# F28x7x_emif_regs register map
Vendor: Texas Instruments
Peripheral module from a debugger description file (folder C2000).
Address unit: 16 bits
Registers are 32-bit, read-write, no defined reset value unless marked. A register's access mark holds for its fields unless they carry their own. Offsets are as the file gives them; lines under a group give offsets from that group; [hi:lo] are bit positions; {n}, {i} and the like mark numbered series; 'fields as' and 'values as' point back to an identical list; <NAME> marks a mode.

## EMIF_REGS
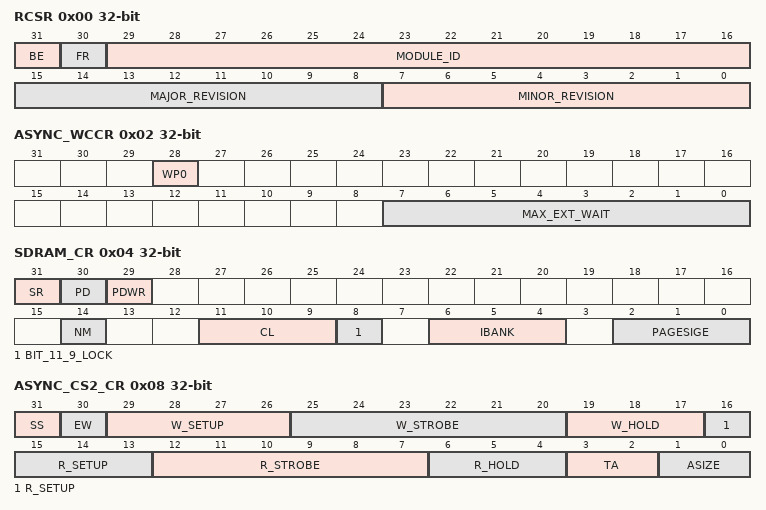
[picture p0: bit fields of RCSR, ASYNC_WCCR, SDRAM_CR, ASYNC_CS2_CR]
0x00 RCSR — Revision Code and Status Register
  [31] BE — EMIF endian mode.
  [30] FR — EMIF is running in full rate or half rate.
  [29:16] MODULE_ID — EMIF module ID.
  [15:8] MAJOR_REVISION
  [7:0] MINOR_REVISION
0x02 ASYNC_WCCR — Async Wait Cycle Config Register
  [28] WP0 — Wait Polarity for EMxWAIT port.
  [7:0] MAX_EXT_WAIT — Maximum Extended Wait cycles.
0x04 SDRAM_CR — SDRAM (EMxCS0n) Config Register
  [31] SR — Self Refresh.
  [30] PD — Power Down.
  [29] PDWR — Perform refreshes during Power Down.
  [14] NM — Narrow Mode.
  [11:9] CL — CAS Latency.
  [8] BIT_11_9_LOCK — Bits 11 to 9 are writable only if this bit is set.
  [6:4] IBANK — Internal Bank setup of SDRAM devices.
  [2:0] PAGESIGE — Page Size.
0x06 SDRAM_RCR — SDRAM Refresh Control Register
  [12:0] REFRESH_RATE
0x08 ASYNC_CS2_CR — Async 1 (EMxCS2n) Config Register
  [31] SS — Select Strobe mode.
  [30] EW — Extend Wait mode.
  [29:26] W_SETUP — Write Strobe Setup cycles.
  [25:20] W_STROBE — Write Strobe Duration cycles.
  [19:17] W_HOLD — Write Strobe Hold cycles.
  [16:13] R_SETUP — Read Strobe Setup cycles.
  [12:7] R_STROBE — Read Strobe Duration cycles.
  [6:4] R_HOLD — Read Strobe Hold cycles.
  [3:2] TA — Turn Around cycles.
  [1:0] ASIZE — Asynchronous Memory Size.
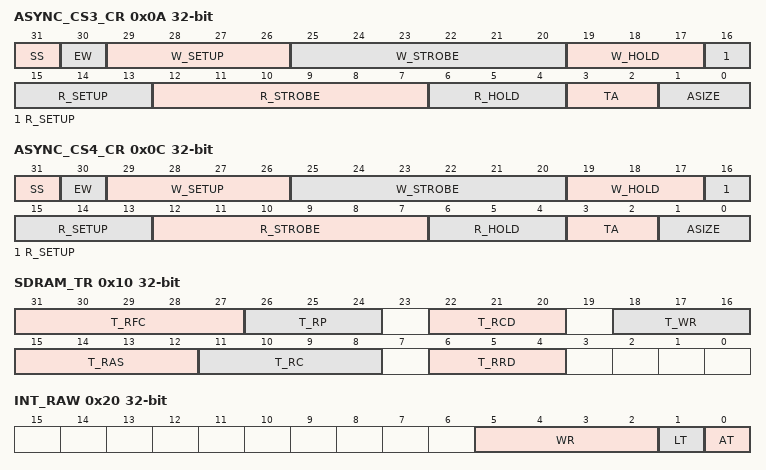
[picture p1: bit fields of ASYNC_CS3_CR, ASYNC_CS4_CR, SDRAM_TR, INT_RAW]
0x0A ASYNC_CS3_CR — Async 2 (EMxCS3n) Config Register
  fields as ASYNC_CS2_CR
0x0C ASYNC_CS4_CR — Async 3 (EMxCS3n) Config Register
  fields as ASYNC_CS2_CR
0x10 SDRAM_TR — SDRAM Timing Register
  [31:27] T_RFC — Refresh/Load Mode to Refresh/Activate timing
  [26:24] T_RP — Precharge to Activate/Refresh timing.
  [22:20] T_RCD — Activate to Read/Write timing.
  [18:16] T_WR — Last Write to Precharge timing.
  [15:12] T_RAS — Activate to Precharge timing.
  [11:8] T_RC — Activate to Activate timing .
  [6:4] T_RRD — Activate to Activate timing for different bank.
0x18 TOTAL_SDRAM_AR — Total SDRAM Accesses Register
  [31:0] TOTAL_SDRAM_AR — Total number of VBUSP accesses to SDRAM.
0x1A TOTAL_SDRAM_ACTR — Total SDRAM Activate Register
  [31:0] TOTAL_SDRAM_ACTR — Number of SDRAM accesses which required an activate command.
0x1E SDR_EXT_TMNG — SDRAM SR/PD Exit Timing Register
  [4:0] T_XS — Self Refresh exit to new command timing.
0x20 INT_RAW — Interrupt Raw Register
  [5:2] WR — Wait Rise.
  [1] LT — Line Trap.
  [0] AT — Asynchronous Timeout.
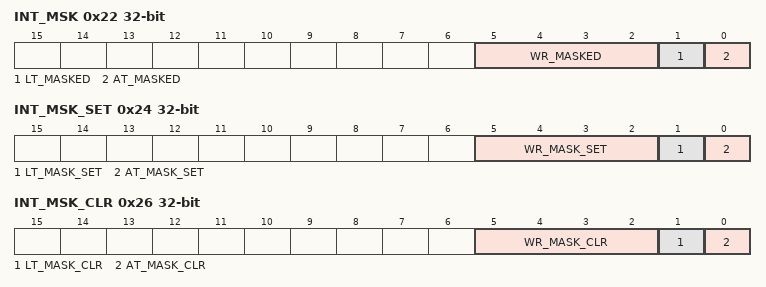
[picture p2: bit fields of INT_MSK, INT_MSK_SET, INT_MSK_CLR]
0x22 INT_MSK — Interrupt Masked Register
  [5:2] WR_MASKED — Wait Rise.
  [1] LT_MASKED — Line Trap.
  [0] AT_MASKED — Asynchronous Timeout.
0x24 INT_MSK_SET — Interrupt Mask Set Register
  [5:2] WR_MASK_SET — Wait Rise.
  [1] LT_MASK_SET — Line Trap.
  [0] AT_MASK_SET — Asynchronous Timeout.
0x26 INT_MSK_CLR — Interrupt Mask Clear Register
  [5:2] WR_MASK_CLR — Wait Rise.
  [1] LT_MASK_CLR — Line Trap.
  [0] AT_MASK_CLR — Asynchronous Timeout.
